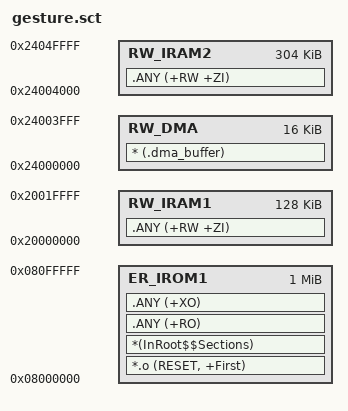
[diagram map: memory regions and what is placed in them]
LR_IROM1 0x08000000 0x00100000 {
  ER_IROM1 0x08000000 0x00100000 {
    *.o (RESET, +First)
    *(InRoot$$Sections)
    .ANY (+RO)
    .ANY (+XO)
  }
  RW_DMA 0x24000000 0x00004000 {
    * (.dma_buffer)
  }
  RW_IRAM1 0x20000000 0x00020000 {
    .ANY (+RW +ZI)
  }
  RW_IRAM2 0x24004000 0x0004C000 {
    .ANY (+RW +ZI)
  }
}
